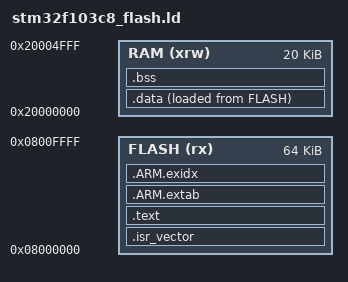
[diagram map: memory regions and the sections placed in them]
/* STM32F103C8T6 (nominal 64 KB Flash, 20 KB SRAM). */
ENTRY(Reset_Handler)

MEMORY
{
  FLASH (rx)  : ORIGIN = 0x08000000, LENGTH = 64K
  RAM (xrw)  : ORIGIN = 0x20000000, LENGTH = 20K
}

__StackTop = ORIGIN(RAM) + LENGTH(RAM);

SECTIONS
{
  .isr_vector :
  {
    . = ALIGN(4);
    KEEP(*(.isr_vector))
    . = ALIGN(4);
  } > FLASH

  .text :
  {
    . = ALIGN(4);
    *(.text*)
    *(.rodata*)
    . = ALIGN(4);
  } > FLASH

  .ARM.extab : { *(.ARM.extab*) } > FLASH
  .ARM.exidx :
  {
    __exidx_start = .;
    *(.ARM.exidx*)
    __exidx_end = .;
  } > FLASH

  .data :
  {
    . = ALIGN(4);
    _sdata = .;
    *(.data*)
    . = ALIGN(4);
    _edata = .;
  } > RAM AT > FLASH
  _sidata = LOADADDR(.data);

  .bss (NOLOAD) :
  {
    . = ALIGN(4);
    _sbss = .;
    *(.bss*)
    *(COMMON)
    . = ALIGN(4);
    _ebss = .;
  } > RAM

  /DISCARD/ : { *(.note.GNU-stack) *(.comment) }
}
